# TIMER_0 register map
Vendor: Texas Instruments
Peripheral module from a debugger description file (folder 66AK2G0x_66AK2G1x).
Registers are 32-bit, read-write, reset 0x0 unless marked. A register's access mark holds for its fields unless they carry their own. Offsets are as the file gives them; lines under a group give offsets from that group; [hi:lo] are bit positions; {n}, {i} and the like mark numbered series; 'fields as' and 'values as' point back to an identical list; <NAME> marks a mode.

## TIMER_0
0x00 TIMER_PID12 ro reset 0x4472020C
  [31:0] REV — TI internal data. Identifies revision of peripheral.
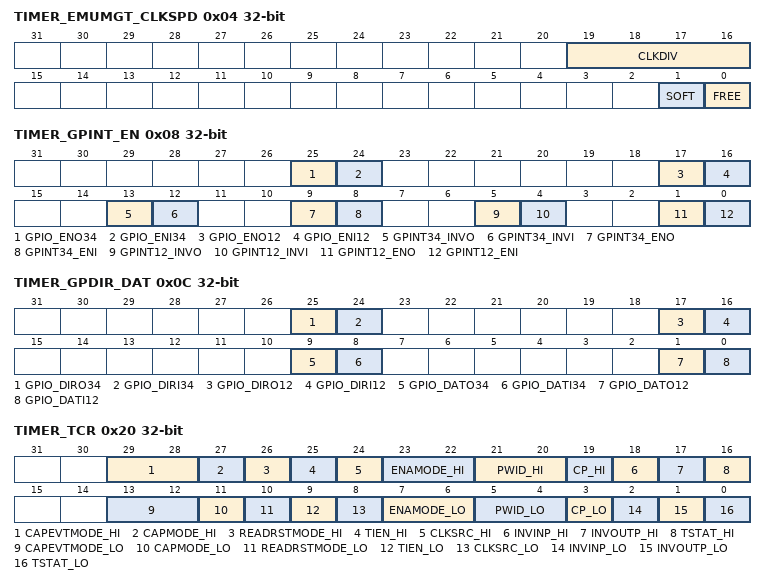
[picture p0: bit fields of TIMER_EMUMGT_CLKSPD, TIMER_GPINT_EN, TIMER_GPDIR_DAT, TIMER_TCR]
0x04 TIMER_EMUMGT_CLKSPD access per field (reset mask 0xFFF0FFFF)
  [19:16] CLKDIV ro — Clock divide-down ratio bits. Defines the ratio of the CPU clock to the timer input clock. The CLKDIV bits are read-only bits.
  [1] SOFT rw — Used in conjunction with FREE bit to determine how the timer responds to an emulation suspend event. When the FREE bit is 0, the SOFT bit selects the timer response.
  [0] FREE rw — Used in conjunction with SOFT bit to determine how the timer responds to an emulation suspend event. When the FREE bit is 0, the SOFT bit selects the timer response.
0x08 TIMER_GPINT_EN
  [25] GPIO_ENO34 — Enable the timer output TOUTH in GPIO mode. GPIO_ENO34=0: timer output functions as a timer output. GPIO_ENO34=1: the timer output is enabled as GPIO.
  [24] GPIO_ENI34 — Enable the timer input TINPH in GPIO mode. GPIO_ENI34=0: timer input functions as a timer input. GPIO_ENI34=1: the timer input is enabled as GPIO.
  [17] GPIO_ENO12 — Enable the timer output TOUTL in GPIO mode. GPIO_ENO12=0: timer output functions as a timer output. GPIO_ENO12=1: the timer output is enabled as GPIO.
  [16] GPIO_ENI12 — Enable the timer input TINPL in GPIO mode. GPIO_ENI12=0: timer input functions as a timer input. GPIO_ENI12=1: the timer input is enabled as GPIO.
  [13] GPINT34_INVO — Invert bit for timer output TOUTH when it is used to source an interrupt or event (GPINT34_ENO=1). GPINT34_INVO=0: Rising of Timer output generate interrupt or event. GPINT34_INVO=1: Falling of Timer output generate interrupt or event. This bit has no effect when GPINT34_ENO=0.
  [12] GPINT34_INVI — Invert bit for timer input TINPH when it is used to source an interrupt or event (GPINT34_ENI=1). GPINT34_INVI=0: Rising of Timer input generate interrupt or event. GPINT34_INVI=1: Falling of Timer input generate interrupt or event. This bit has no effect when GPINT34_ENI=0.
  [9] GPINT34_ENO — Enable the timer output TOUTH to source the interrupt or event in GPIO mode. GPINT34_ENO=0: causes the interrupt or event to be sourced normally by the timer. GPINT34_ENO=1: causes the timer output to source an interrupt or event.
  [8] GPINT34_ENI — Enable the timer input TINPH to source the interrupt or event in GPIO mode. GPINT34_ENI=0: causes the interrupt or event to be sourced normally by the timer. GPINT34_ENI=1: causes the timer input to source an interrupt or event.
  [5] GPINT12_INVO — Invert bit for timer output TOUTL when it is used to source an interrupt or event (GPINT12_ENO=1). GPINT12_INVO=0: Timer output interrupt or event is not inverted. GPINT12_INVO=1: Timer output interrupt or event is inverted. This bit has no effect when GPINT12_ENO=0.
  [4] GPINT12_INVI — Invert bit for timer input TINPL when it is used to source an interrupt or event (GPINT12_ENI=1). GPINT12_INVI=0: Timer input interrupt or event is not inverted. GPINT12_INVI=1: Timer input interrupt or event is inverted. This bit has no effect when GPINT12_ENI=0.
  [1] GPINT12_ENO — Enable the timer output TOUTL to source the interrupt or event in GPIO mode. GPINT12_ENO=0: causes the interrupt or event to be sourced normally by the timer. GPINT12_ENO=1: causes the timer output to source an interrupt or event.
  [0] GPINT12_ENI — Enable the timer input TINPL to source the interrupt or event in GPIO mode. GPINT12_ENI=0: causes the interrupt or event to be sourced normally by the timer. GPINT12_ENI=1: causes the timer input to source an interrupt or event.
0x0C TIMER_GPDIR_DAT
  [25] GPIO_DIRO34 — Controls the direction of the timer output TOUTH in GPIO mode. It must be set to 0 to be used as input in GPIO interrupt mode. GPIO_DIRO34=0: timer output functions as a GPIO input. GPIO_DIRO34=1: timer output functions as a GPIO output.
  [24] GPIO_DIRI34 — Controls the direction of the timer input TINPH in GPIO mode. It must be set to 0 to be used as input in GPIO interrupt mode. GPIO_DIRI34=0: timer input functions as a GPIO input. GPIO_DIRI34=1: timer input functions as a GPIO output.
  [17] GPIO_DIRO12 — Controls the direction of the timer output TOUTL in GPIO mode. It must be set to 0 to be used as input in GPIO interrupt mode. GPIO_DIRO12=0: timer output functions as a GPIO input. GPIO_DIRO12=1: timer output functions as a GPIO output.
  [16] GPIO_DIRI12 — Controls the direction of the timer input TINPL in GPIO mode. It must be set to 0 to be used as input in GPIO interrupt mode. GPIO_DIRI12=0: timer input functions as a GPIO input. GPIO_DIRI12=1: timer input functions as a GPIO output.
  [9] GPIO_DATO34 — When GPIO_DIRO34=0: timer output TOUTH functions as a GPIO input, the logic value read in this bit is equal to the logic level present at the timer input. Writes to this bit have no effect. The GP input is sampled with the VBUS clock. When GPIO_DIRO34=1: timer output TOUTH functions as a GPIO output, the GP output is driven to the logic level which is written to and stored in this bit. The logic level of the GP output can also be read back at this bit.
  [8] GPIO_DATI34 — When GPIO_DIRI34=0: timer input TINPH functions as a GPIO input, the logic value read in this bit is equal to the logic level present at the timer input. Writes to this bit have no effect. The GP input is sampled with the VBUS clock. When GPIO_DIRI=1: timer input functions as a GPIO output, the GP output is driven to the logic level which is written to and stored in this bit. The logic level of the GP output can also be read back at this bit.
  [1] GPIO_DATO12 — When GPIO_DIRO12=0: timer output TOUTL functions as a GPIO input, the logic value read in this bit is equal to the logic level present at the timer input. Writes to this bit have no effect. The GP input is sampled with the VBUS clock. When GPIO_DIRO=1: timer output TOUTL functions as a GPIO output, the GP output is driven to the logic level which is written to and stored in this bit. The logic level of the GP output can also be read back at this bit.
  [0] GPIO_DATI12 — When GPIO_DIRI12=0: timer input TINPL functions as a GPIO input, the logic value read in this bit is equal to the logic level present at the timer input. Writes to this bit have no effect. The GP input is sampled with the VBUS clock. When GPIO_DIRI12=1: timer input TINPL functions as a GPIO output, the GP output is driven to the logic level which is written to and stored in this bit. The logic level of the GP output can also be read back at this bit.
0x10 TIMER_CNTLO
  [31:0] CNT — Value = 0000 0000h-FFFF FFFFhCounter register. This register is a 32-bit prescale counter or 32-bit timer counter, or one half of a 64-bit timer counter.
0x14 TIMER_CNTHI
  fields as TIMER_CNTLO
0x18 TIMER_PRDLO
  [31:0] PRD — Value = 0000 0000h-FFFF FFFFhPeriod register. This register contains the full timer period for a 32-bit timer configuration or half the timer period for a 64-bit timer configuration.
0x1C TIMER_PRDHI
  fields as TIMER_PRDLO
0x20 TIMER_TCR access per field
  [29:28] CAPEVTMODE_HI rw — Capture event mode for TIMHI. Uses these bits to specify the type of event for Capture mode.
  [27] CAPMODE_HI rw — Capture mode enable bit for TIMHI. Determines if external event can reset timer. Capture mode is only available in dual 32-bit unchained mode and when CLKSRC = 0 and ENAMODE = 2h or 3h.Output events (interrupt/DMA/other) are generated when capture mode event occurs.
  [26] READRSTMODE_HI rw — Read reset mode enable bit for TIMHI. Determines the effect of a timer counter read onTIMER_CNTHI. Read reset mode is only available in dual 32-bit unchained. Output events (interrupt/DMA/other) are not generated when read reset occurs.
  [25] TIEN_HI rw — Timer input enable bit determines if the timer clock is gated by the timer input. Applicable only when CLKSRC_HI = 0.
  [24] CLKSRC_HI rw — Clock source bit determines the clock source for the timer.
  [23:22] ENAMODE_HI rw — A value written to this Enabling mode bits determine the timer mode for TIMHI.
  [21:20] PWID_HI rw — Pulse width bits for TIMHI. PWID_HI is only used in pulse mode (CP_HI = 0). PWID_HI controls the width of the timer output signal. The polarity of the pulse is controlled by the INVOUTP_HI bit. The timer output signal is recorded in the TSTAT_HI bit and can be made visible on the timer output pin.
  [19] CP_HI rw — Clock/pulse mode bit for TIMHI. In the watchdog timer mode (TIMMODE = 2h), the pulse mode is selected automatically and the CP_HI bit is a don’t care.
  [18] INVINP_HI rw — Timer input inverter control bit for TIMHI. Only affects operation if CLKSRC_HI = 1.
  [17] INVOUTP_HI rw — Timer output inverter control bit for TIMHI.
  [16] TSTAT_HI rw — Timer status bit for TIMHI. This is a read-only bit that shows the value of the timer output.
  [13:12] CAPEVTMODE_LO rw — Capture event mode. Uses these bits to specify the type of event for Capture mode.
  [11] CAPMODE_LO rw — Capture mode enable bit. Determines if external event can reset timer. Capture mode is only available in dual 32-bit unchained mode and when CLKSRC = 0 and ENAMODE = 2h or 3h.Output events (interrupt/DMA/other) are generated when capture mode event occurs.
  [10] READRSTMODE_LO rw — Read reset mode enable bit. Determines the effect of a timer counter read onTIMER_CNTLO. Read reset mode is only available in dual 32-bit unchained. Output events (interrupt/DMA/other) are not generated when read reset occurs.
  [9] TIEN_LO rw — Timer input enable bit determines if the timer clock is gated by the timer input. Applicable only when CLKSRC_LO = 0.
  [8] CLKSRC_LO rw — Clock source bit determines the clock source for the timer.
  [7:6] ENAMODE_LO rw — Enabling mode bits determine the timer mode.
  [5:4] PWID_LO rw — Pulse width bits. PWID_LO is only used in pulse mode (CP_LO = 0). PWID_LO controls the width of the timer output signal. The polarity of the pulse is controlled by the INVOUTP_LO bit. The timer output signal is recorded in the TSTAT_LO bit and can be made visible on the timer output pin.
  [3] CP_LO rw — Clock/pulse mode bit for timer output. In the watchdog timer mode (TIMMODE = 2h), the pulse mode is selected automatically and the CP_LO bit is a don’t care.
  [2] INVINP_LO rw — Timer input inverter control bit. Only affects operation if CLKSRC_LO = 1.
  [1] INVOUTP_LO rw — Timer output inverter control bit.
  [0] TSTAT_LO rw — Timer status bit. This is a read-only bit that shows the value of the timer output. TSTAT_LO drives the timer pin (TOUTL) when the pin is used as a timer output pin and may be inverted by setting INVOUTP_LO = 1.
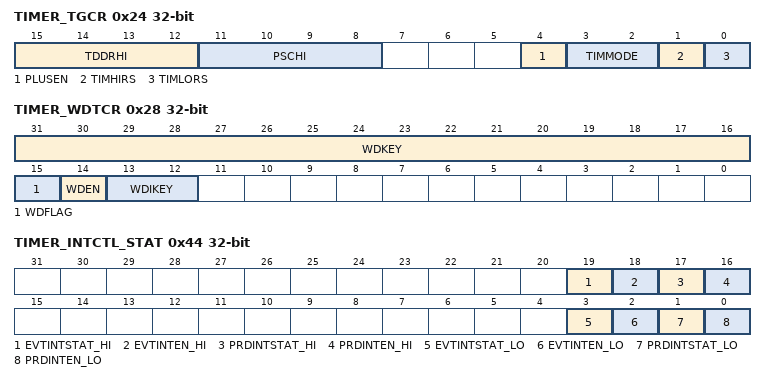
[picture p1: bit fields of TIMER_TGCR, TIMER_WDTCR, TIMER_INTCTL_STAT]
0x24 TIMER_TGCR
  [15:12] TDDRHI — Timer divide-down ratio bits. This field is the prescale counter for TIMHI in the dual 32-bit timers unchained mode (TIMMODE = 1h). When the timer is enabled, TDDRHI increments every timer clock cycle. The timer counter (TIMER_CNTHI) increments on the cycle after the TDDRHI matches the value of PSCHI. TDDRHI resets to 0 and continues. If enabled one time, when TIMER_CNTHI matches the TIMER_PRDHI, the timer stops; if the timer is enabled continuously, TIMER_CNTHI resets to 0 on the cycle after matching the TIMER_PRDHI and the timer continues counting. The default value is 0000h.
  [11:8] PSCHI — Prescale period bits. This field specifies the prescale period for TIMHI in the dual 32-bit timers unchained mode (TIMMODE = 1h). The default value is 0000h.
  [4] PLUSEN — Enable Timer Plus features.
  [3:2] TIMMODE — Timer mode bits determine the timer operating mode.
  [1] TIMHIRS — TIMHI reset bit. Note that in order for the timer to function properly in 64-bit general-purpose timer mode both the TIMHIRS and TIMLORS bits must be set to 1. If the timer is in the watchdog timer active state, changing this bit does not affect the timer.
  [0] TIMLORS — TIMLO reset bit. Note that in order for the timer to function properly in 64-bit general-purpose timer mode both the TIMHIRS and TIMLORS bits must be set to 1. If the timer is in the watchdog timer active state, changing this bit does not affect the timer.
0x28 TIMER_WDTCR
  [31:16] WDKEY — Value = 0000h-FFFFhWatchdog timer service key bits. Before a watchdog timeout event occurs, only a write sequence of a A5C6h followed by a DA7Eh services the watchdog timer. Any other write triggers a watchdog timeout event immediately. The default value of WDKEY is 0000h. WDKEY is not applicable in the general-purpose timer mode.
  [15] WDFLAG — Watchdog timer flag bit. WDFLAG is cleared when the watchdog timer is moved to the active state, when a hardware reset occurs, and when 1 is written to WDFLAG.
  [14] WDEN — Watchdog timer enable bit. WDEN must be set to move the watchdog timer to the pre-active state (see).
  [13:12] WDIKEY — Value = 0h-3hWatchdog idle enable key bits. A write sequence of 1h followed by 2h is required before the watchdog timer can enter the idle mode. Writing 0h to WDIKEY prevents the watchdog timer from entering the idle mode. WDIKEY is not applicable in the general-purpose timer mode.
0x34 TIMER_RELLO
  [31:0] REL — Value = 0000 0000h-FFFF FFFFhReload register. This register contains the full timer reload for a 32-bit timer configuration or half the timer reload for a 64-bit timer configuration.
0x38 TIMER_RELHI
  fields as TIMER_RELLO
0x3C TIMER_CAPLO
  [31:0] CAP — Value = 0000 0000h-FFFF FFFFhCapture register. Captured timer counter bits.
0x40 TIMER_CAPHI
  fields as TIMER_CAPLO
0x44 TIMER_INTCTL_STAT
  [19] EVTINTSTAT_HI — Interrupt status which reflects the condition that an external event caused a timeout when timer is in capture mode. Write a 1 to clear this bit.
  [18] EVTINTEN_HI — Enables the interrupt generation when timer is in capture mode.
  [17] PRDINTSTAT_HI — Interrupt status which reflects the condition that timer counter matched the period register when timer is enabled. Write a 1 to clear this bit.
  [16] PRDINTEN_HI — Enable interrupt generation when timer is enabled in 64-bit/32-bit chained/unchained/watchdog modes.
  [3] EVTINTSTAT_LO — Interrupt status which reflects the condition that an external event caused a timeout when timer is in capture mode. Write a 1 to clear this bit.
  [2] EVTINTEN_LO — Enables the interrupt generation when timer is in capture mode.
  [1] PRDINTSTAT_LO — Interrupt status which reflects the condition that timer counter matched the period register when timer is enabled. Write a 1 to clear this bit.
  [0] PRDINTEN_LO — Enable interrupt generation when timer is enabled in 64-bit/32-bit chained/unchained/watchdog modes.
